# ESP32-P4 register map
Vendor: ESPRESSIF SYSTEMS (SHANGHAI) CO., LTD.; Series: ESP32 P-Series; File version: 3
CPU: RV32IMAFC r0p0, little endian, no MPU, FPU, 0 interrupt priority bits
Address unit: 32 bits
Registers are 32-bit, read-write, reset 0x0 unless marked. A register's access mark holds for its fields unless they carry their own. Offsets are from the block's base; [hi:lo] are bit positions; {n}, {i} and the like mark numbered series; 'fields as' and 'values as' point back to an identical list.

## MEMSPI3 — Memory SPI 3
Base 0x5008F000
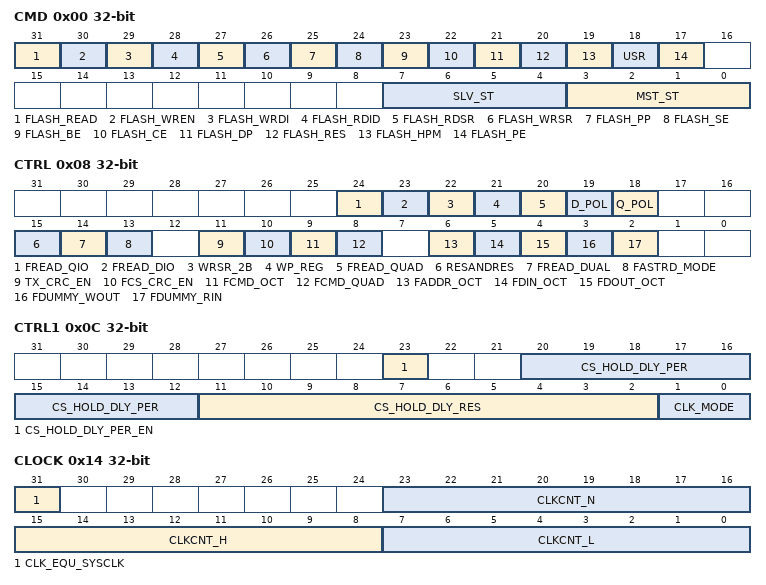
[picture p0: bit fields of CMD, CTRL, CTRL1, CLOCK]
0x00 CMD access per field
  [31] FLASH_READ rw, [30] FLASH_WREN rw, [29] FLASH_WRDI rw, [28] FLASH_RDID rw, [27] FLASH_RDSR rw, [26] FLASH_WRSR rw, [25] FLASH_PP rw, [24] FLASH_SE rw, [23] FLASH_BE rw, [22] FLASH_CE rw, [21] FLASH_DP rw, [20] FLASH_RES rw, [19] FLASH_HPM rw, [18] USR rw, [17] FLASH_PE rw, [7:4] SLV_ST ro, [3:0] MST_ST ro
0x04 ADDR
  [31:0] USR_ADDR_VALUE
0x08 CTRL
  [24] FREAD_QIO, [23] FREAD_DIO, [22] WRSR_2B, [21] WP_REG, [20] FREAD_QUAD, [19] D_POL, [18] Q_POL, [15] RESANDRES, [14] FREAD_DUAL, [13] FASTRD_MODE, [11] TX_CRC_EN, [10] FCS_CRC_EN, [9] FCMD_OCT, [8] FCMD_QUAD, [6] FADDR_OCT, [5] FDIN_OCT, [4] FDOUT_OCT, [3] FDUMMY_WOUT, [2] FDUMMY_RIN
0x0C CTRL1
  [23] CS_HOLD_DLY_PER_EN, [20:12] CS_HOLD_DLY_PER, [11:2] CS_HOLD_DLY_RES, [1:0] CLK_MODE
0x10 CTRL2 wo
  [31] SYNC_RESET
0x14 CLOCK
  [31] CLK_EQU_SYSCLK, [23:16] CLKCNT_N, [15:8] CLKCNT_H, [7:0] CLKCNT_L
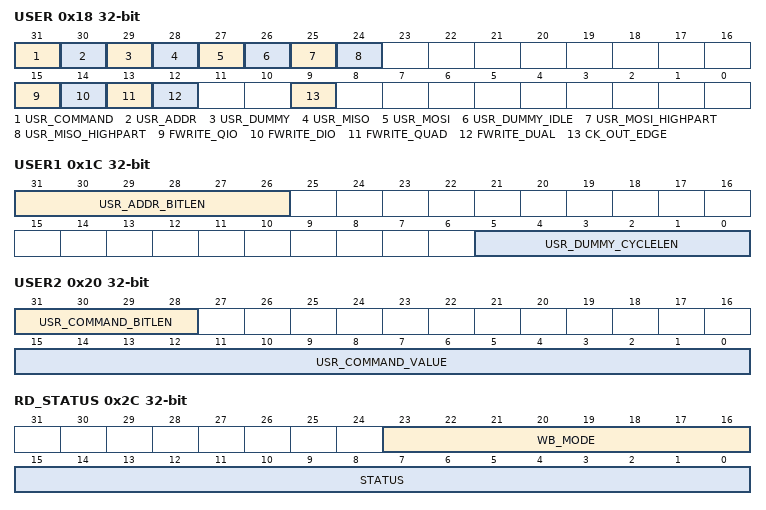
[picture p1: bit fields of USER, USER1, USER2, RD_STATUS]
0x18 USER
  [31] USR_COMMAND, [30] USR_ADDR, [29] USR_DUMMY, [28] USR_MISO, [27] USR_MOSI, [26] USR_DUMMY_IDLE, [25] USR_MOSI_HIGHPART, [24] USR_MISO_HIGHPART, [15] FWRITE_QIO, [14] FWRITE_DIO, [13] FWRITE_QUAD, [12] FWRITE_DUAL, [9] CK_OUT_EDGE
0x1C USER1
  [31:26] USR_ADDR_BITLEN, [5:0] USR_DUMMY_CYCLELEN
0x20 USER2
  [31:28] USR_COMMAND_BITLEN, [15:0] USR_COMMAND_VALUE
0x24 MOSI_DLEN
  [9:0] USR_MOSI_DBITLEN
0x28 MISO_DLEN
  [9:0] USR_MISO_DBITLEN
0x2C RD_STATUS
  [23:16] WB_MODE, [15:0] STATUS
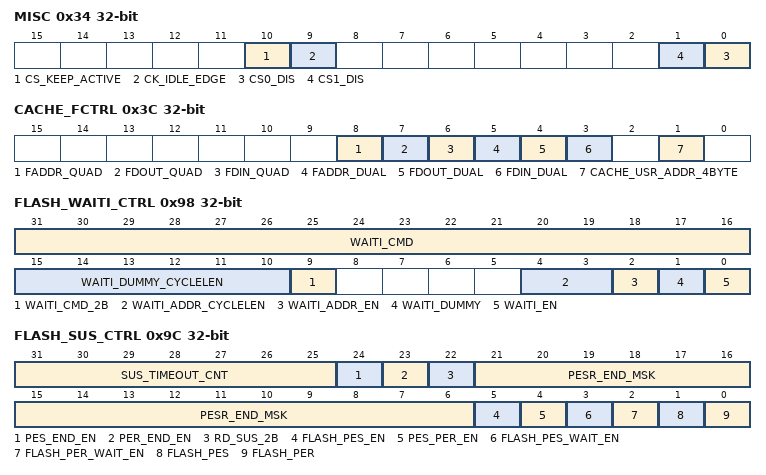
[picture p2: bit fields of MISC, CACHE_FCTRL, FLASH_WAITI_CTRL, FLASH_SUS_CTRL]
0x34 MISC
  [10] CS_KEEP_ACTIVE, [9] CK_IDLE_EDGE, [n] CS{n}_DIS (n=0..1)
0x38 TX_CRC ro
  [31:0] DATA
0x3C CACHE_FCTRL
  [8] FADDR_QUAD, [7] FDOUT_QUAD, [6] FDIN_QUAD, [5] FADDR_DUAL, [4] FDOUT_DUAL, [3] FDIN_DUAL, [1] CACHE_USR_ADDR_4BYTE
{0x58+4i} W{i} (i=0..15) reset 0xFFFFFFFF
  [31:0] BUF
0x98 FLASH_WAITI_CTRL
  [31:16] WAITI_CMD, [15:10] WAITI_DUMMY_CYCLELEN, [9] WAITI_CMD_2B, [4:3] WAITI_ADDR_CYCLELEN, [2] WAITI_ADDR_EN, [1] WAITI_DUMMY, [0] WAITI_EN
0x9C FLASH_SUS_CTRL
  [31:25] SUS_TIMEOUT_CNT, [24] PES_END_EN, [23] PER_END_EN, [22] RD_SUS_2B, [21:6] PESR_END_MSK, [5] FLASH_PES_EN, [4] PES_PER_EN, [3] FLASH_PES_WAIT_EN, [2] FLASH_PER_WAIT_EN, [1] FLASH_PES, [0] FLASH_PER
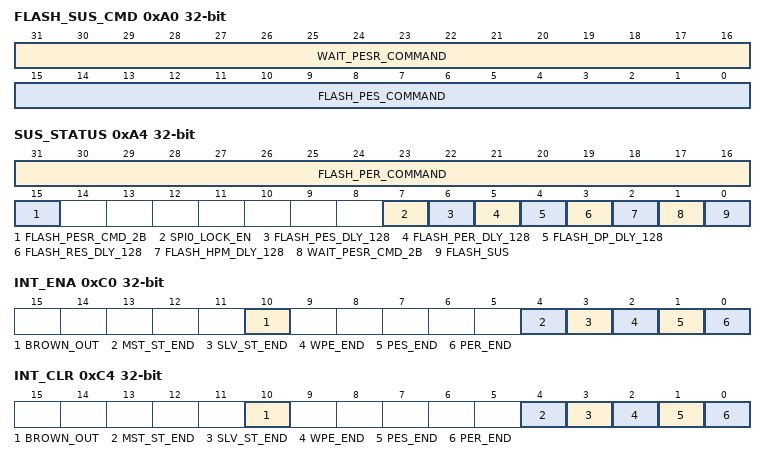
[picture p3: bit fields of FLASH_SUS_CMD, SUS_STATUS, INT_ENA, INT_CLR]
0xA0 FLASH_SUS_CMD
  [31:16] WAIT_PESR_COMMAND, [15:0] FLASH_PES_COMMAND
0xA4 SUS_STATUS
  [31:16] FLASH_PER_COMMAND, [15] FLASH_PESR_CMD_2B, [7] SPI0_LOCK_EN, [6] FLASH_PES_DLY_128, [5] FLASH_PER_DLY_128, [4] FLASH_DP_DLY_128, [3] FLASH_RES_DLY_128, [2] FLASH_HPM_DLY_128, [1] WAIT_PESR_CMD_2B, [0] FLASH_SUS
0xC0 INT_ENA
  [10] BROWN_OUT, [4] MST_ST_END, [3] SLV_ST_END, [2] WPE_END, [1] PES_END, [0] PER_END
0xC4 INT_CLR wo
  [10] BROWN_OUT write-1-clears, [4] MST_ST_END write-1-clears, [3] SLV_ST_END write-1-clears, [2] WPE_END write-1-clears, [1] PES_END write-1-clears, [0] PER_END write-1-clears
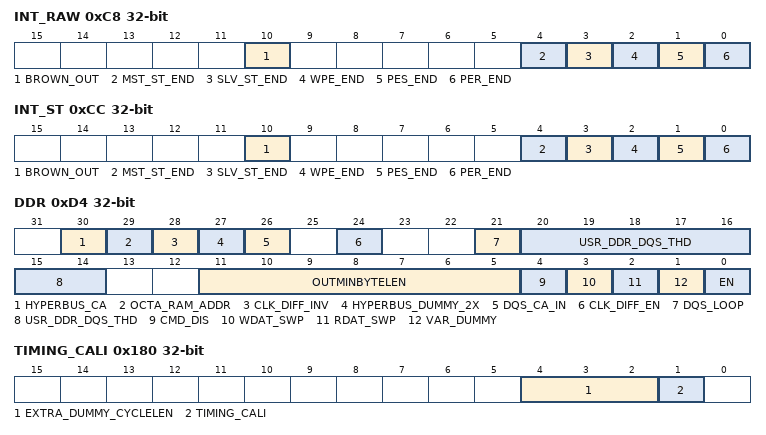
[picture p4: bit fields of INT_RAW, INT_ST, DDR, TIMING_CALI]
0xC8 INT_RAW
  fields as INT_ENA
0xCC INT_ST ro
  fields as INT_ENA
0xD4 DDR
  [30] HYPERBUS_CA, [29] OCTA_RAM_ADDR, [28] CLK_DIFF_INV, [27] HYPERBUS_DUMMY_2X, [26] DQS_CA_IN, [24] CLK_DIFF_EN, [21] DQS_LOOP, [20:14] USR_DDR_DQS_THD, [11:5] OUTMINBYTELEN, [4] CMD_DIS, [3] WDAT_SWP, [2] RDAT_SWP, [1] VAR_DUMMY, [0] EN
0x180 TIMING_CALI
  [4:2] EXTRA_DUMMY_CYCLELEN, [1] TIMING_CALI
0x200 CLOCK_GATE
  [0] CLK_EN
0x3FC DATE
  [27:0] DATE

## LP_TSENS — Low-power Temperature Sensor
Base 0x5012F000
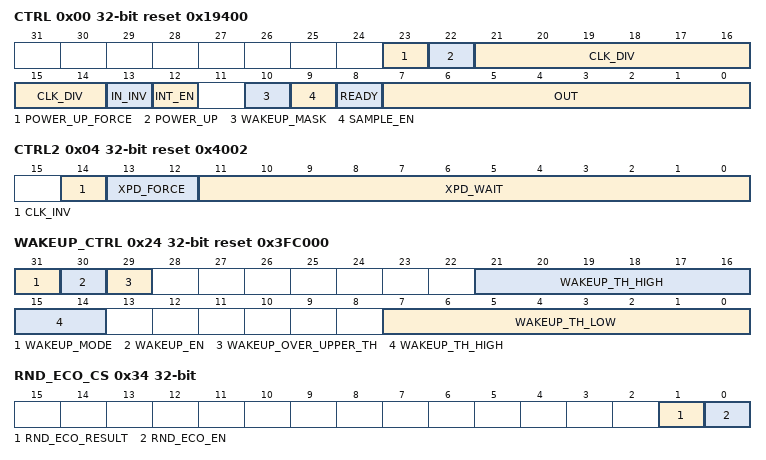
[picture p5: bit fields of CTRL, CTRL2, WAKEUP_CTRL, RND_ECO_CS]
0x00 CTRL access per field reset 0x19400 — Tsens configuration.
  [23] POWER_UP_FORCE rw — 1: dump out & power up controlled by SW, 0: by FSM.
  [22] POWER_UP rw — Temperature sensor power up.
  [21:14] CLK_DIV rw — Temperature sensor clock divider.
  [13] IN_INV rw — Invert temperature sensor data.
  [12] INT_EN rw — Enable temperature sensor to send out interrupt.
  [10] WAKEUP_MASK rw — Wake up signal mask.
  [9] SAMPLE_EN rw — Enable sample signal for wakeup module.
  [8] READY ro — Indicate temperature sensor out ready.
  [7:0] OUT ro — Temperature sensor data out.
0x04 CTRL2 reset 0x4002 — Tsens configuration.
  [14] CLK_INV, [13:12] XPD_FORCE, [11:0] XPD_WAIT
0x08 INT_RAW — Tsens interrupt raw registers.
  [0] COCPU_TSENS_WAKE_INT_RAW — Tsens wakeup interrupt raw.
0x0C INT_ST ro — Tsens interrupt status registers.
  [0] COCPU_TSENS_WAKE_INT_ST — Tsens wakeup interrupt status.
0x10 INT_ENA — Tsens interrupt enable registers.
  [0] COCPU_TSENS_WAKE_INT_ENA — Tsens wakeup interrupt enable.
0x14 INT_CLR wo — Tsens interrupt clear registers.
  [0] COCPU_TSENS_WAKE_INT_CLR — Tsens wakeup interrupt clear.
0x18 CLK_CONF — Tsens regbank configuration registers.
  [0] CLK_EN — Tsens regbank clock gating enable.
0x1C INT_ENA_W1TS wo — Tsens wakeup interrupt enable assert.
  [0] COCPU_TSENS_WAKE_INT_ENA_W1TS — Write 1 to this field to assert interrupt enable.
0x20 INT_ENA_W1TC wo — Tsens wakeup interrupt enable deassert.
  [0] COCPU_TSENS_WAKE_INT_ENA_W1TC — Write 1 to this field to deassert interrupt enable.
0x24 WAKEUP_CTRL access per field reset 0x3FC000 — Tsens wakeup control registers.
  [31] WAKEUP_MODE rw — 0:absolute value comparison mode. 1: relative value comparison mode.
  [30] WAKEUP_EN rw — Tsens wakeup enable.
  [29] WAKEUP_OVER_UPPER_TH ro — Indicates that this wakeup event arose from exceeding upper threshold.
  [21:14] WAKEUP_TH_HIGH rw — Upper threshold.
  [7:0] WAKEUP_TH_LOW rw — Lower threshold.
0x28 SAMPLE_RATE reset 0x14 — Hardware automatic sampling control registers.
  [15:0] SAMPLE_RATE — Hardware automatic sampling rate.
0x2C RND_ECO_LOW
0x30 RND_ECO_HIGH reset 0xFFFFFFFF
0x34 RND_ECO_CS access per field
  [1] RND_ECO_RESULT ro, [0] RND_ECO_EN rw

## USB_WRAP — USB_WRAP Peripheral
Base 0x50080000
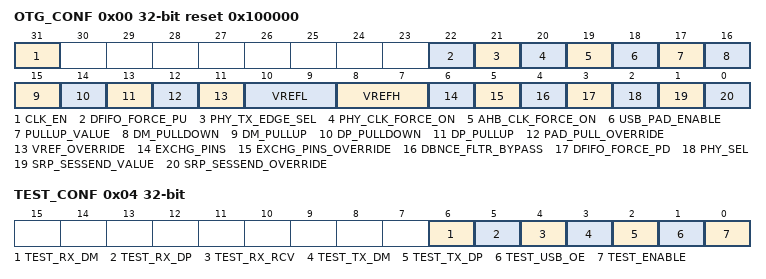
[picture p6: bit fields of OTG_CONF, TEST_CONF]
0x00 OTG_CONF reset 0x100000 — USB wrapper configuration registers.
  [31] CLK_EN — Disable auto clock gating of CSR registers.
  [22] DFIFO_FORCE_PU — Disable the dfifo to go into low power mode. The data in dfifo will not lost.
  [21] PHY_TX_EDGE_SEL — Select phy tx signal output clock edge. 1'b0: negedge, 1'b1: posedge.
  [20] PHY_CLK_FORCE_ON — Force phy clock always on.
  [19] AHB_CLK_FORCE_ON — Force ahb clock always on.
  [18] USB_PAD_ENABLE — Enable USB pad function.
  [17] PULLUP_VALUE — Controlle pullup value. 1'b0: typical value is 2.4K, 1'b1: typical value is 1.2K.
  [16] DM_PULLDOWN — Controlle USB D+ pulldown.
  [15] DM_PULLUP — Controlle USB D+ pullup.
  [14] DP_PULLDOWN — Controlle USB D+ pulldown.
  [13] DP_PULLUP — Controlle USB D+ pullup.
  [12] PAD_PULL_OVERRIDE — Enable software controlle USB D+ D- pullup pulldown.
  [11] VREF_OVERRIDE — Enable software controlle input threshold.
  [10:9] VREFL — Control single-end input low threshold,0.8V to 1.04V, step 80mV.
  [8:7] VREFH — Control single-end input high threshold,1.76V to 2V, step 80mV.
  [6] EXCHG_PINS — USB D+ D- exchange. 1'b0: don't change, 1'b1: exchange D+ D-.
  [5] EXCHG_PINS_OVERRIDE — Enable software controlle USB D+ D- exchange
  [4] DBNCE_FLTR_BYPASS — Bypass Debounce filters for avalid,bvalid,vbusvalid,session end, id signals
  [3] DFIFO_FORCE_PD — Force the dfifo to go into low power mode. The data in dfifo will not lost.
  [2] PHY_SEL — Select internal external PHY. 1'b0: Select internal PHY, 1'b1: Select external PHY.
  [1] SRP_SESSEND_VALUE — Software over-ride value of srp session end signal.
  [0] SRP_SESSEND_OVERRIDE — This bit is used to enable the software over-ride of srp session end signal. 1'b0: the signal is controlled by the chip input, 1'b1: the signal is controlled by the software.
0x04 TEST_CONF access per field — USB wrapper test configuration registers.
  [6] TEST_RX_DM ro — USB D- rx value in test.
  [5] TEST_RX_DP ro — USB D+ rx value in test.
  [4] TEST_RX_RCV ro — USB differential rx value in test.
  [3] TEST_TX_DM rw — USB D- tx value in test.
  [2] TEST_TX_DP rw — USB D+ tx value in test.
  [1] TEST_USB_OE rw — USB pad oen in test.
  [0] TEST_ENABLE rw — Enable test of the USB pad.
0x3FC DATE ro reset 0x23030504
  [31:0] USB_WRAP_DATE
